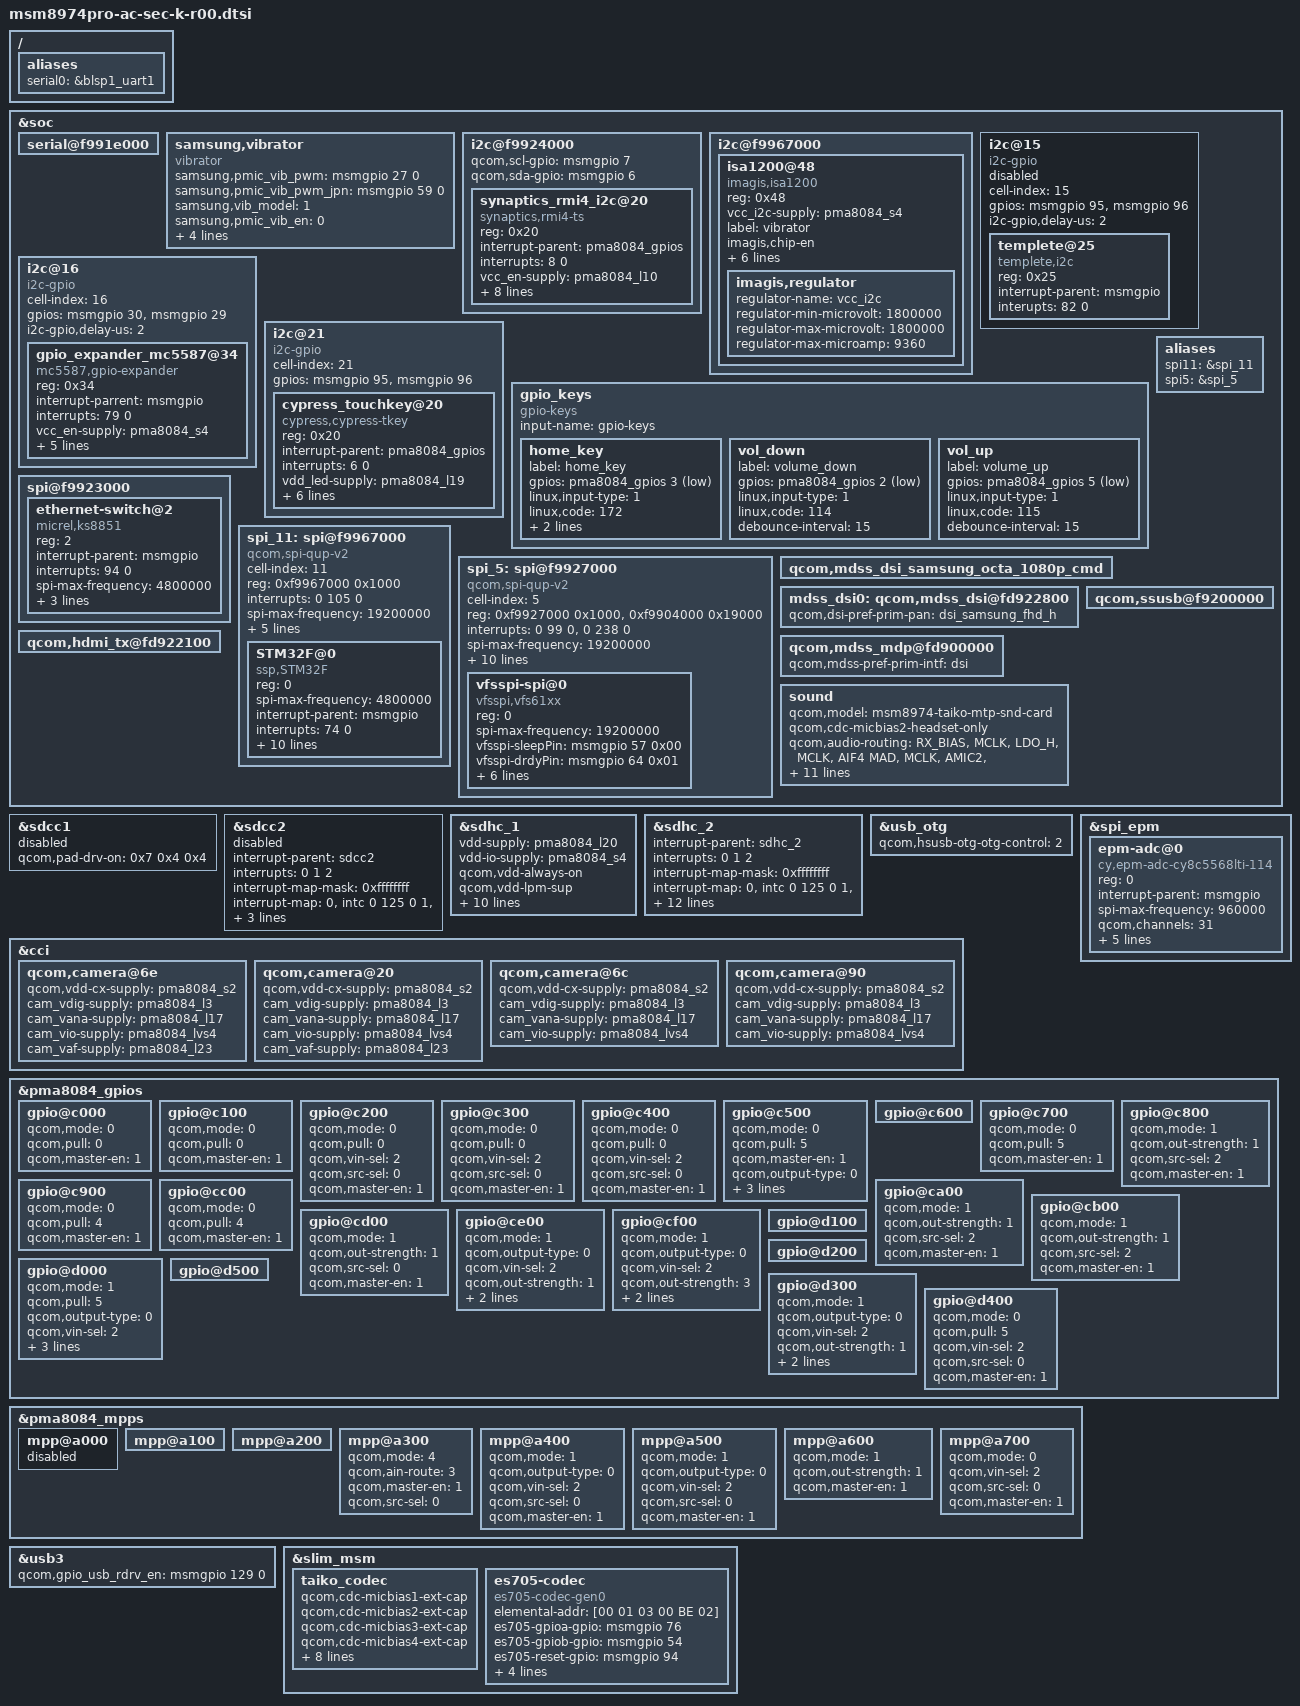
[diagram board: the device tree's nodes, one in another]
/* Copyright (c) 2013, The Linux Foundation. All rights reserved.
 *
 * This program is free software; you can redistribute it and/or modify
 * it under the terms of the GNU General Public License version 2 and
 * only version 2 as published by the Free Software Foundation.
 *
 * This program is distributed in the hope that it will be useful,
 * but WITHOUT ANY WARRANTY; without even the implied warranty of
 * MERCHANTABILITY or FITNESS FOR A PARTICULAR PURPOSE.  See the
 * GNU General Public License for more details.
 */

/*/include/ "msm8974-camera-sensor-mtp.dtsi"*/
/include/ "msm8974pro-sii8240_mhl-k-r00.dtsi"

/ {
	aliases {
		serial0 = &blsp1_uart1;
	};
};

&soc {
	serial@f991e000 {
		status = "ok";
	};
	
	samsung,vibrator {
		compatible = "vibrator";
		samsung,pmic_vib_pwm = <&msmgpio 27 0>;
		samsung,pmic_vib_pwm_jpn = <&msmgpio 59 0>;
		samsung,vib_model = <1>;
		samsung,pmic_vib_en = <0>;
		samsung,pmic_haptic_pwr_en = <0>;
		samsung,is_pmic_vib_pwm = <0>;
		samsung,pwm_period_us = <40>;
		samsung,duty_us = <36>;
		status = "ok";
	};

	i2c@f9924000 {
	qcom,scl-gpio = <&msmgpio 7 0>;
	qcom,sda-gpio = <&msmgpio 6 0>;

	synaptics_rmi4_i2c@20 {
			compatible = "synaptics,rmi4-ts";
			reg = <0x20>;
			interrupt-parent = <&pma8084_gpios>;
			interrupts = <8 0>;
			vcc_en-supply = <&pma8084_l10>;
			synaptics,supply-num = <1>;		/* the number of regulators */
			synaptics,supply-name = "8084_l10";	/* the name of regulators, in power-on order */
			synaptics,external_ldo = <&pma8084_gpios 9 0x1>;
			synaptics,irq-gpio = <&pma8084_gpios 8 0x1>;
			synaptics,tsp-coords = <1079 1919>;
			synaptics,i2c-pull-up = <1>;
			synaptics,tsp-project = "K";
			synaptics,tsp-extra_config = <1 0 0 0>;/* <"pwrctrl", "N", "N", "N"> */
		};
	};
	
	i2c@f9967000 {
	   isa1200@48 {
     status = "okay";
	   reg = <0x48>;
	   vcc_i2c-supply = <&pma8084_s4>;
	   compatible = "imagis,isa1200";
	   label = "vibrator";
	   imagis,chip-en;
	   imagis,need-pwm-clk;
	   imagis,ext-clk-en;
	   imagis,hap-en-gpio = <&msmgpio 86 0x00>;
	   imagis,max-timeout = <15000>;
	   imagis,pwm-div = <256>;
	   imagis,mode-ctrl = <2>;
	   imagis,regulator {
			  	regulator-name = "vcc_i2c";
				  regulator-min-microvolt = <1800000>;
				  regulator-max-microvolt = <1800000>;
				  regulator-max-microamp = <9360>;
			};
		};
	};
/*
	i2c@f9928000 {
	  	gpio_expander_mc5587@34 {
			compatible = "mc5587,gpio-expander";
			reg = <0x34>;
			vcc_en-supply = <&pma8084_s4>;
		};
	};
*/

	/* templete of i2c-gpio */
	  i2c@15{
	      cell-index = <15>;
	      compatible = "i2c-gpio";
	      gpios = <&msmgpio 95 0  /*SDA*/
        	      &msmgpio 96 0  /*SCL*/
	             >;
	      i2c-gpio,delay-us = <2>;
	      #address-cells = <1>;
	      #size-cells = <0>;
		status = "disabled"; /*just templete, and then disable it
			       don't care all property despite of duplication */
	      templete@25{
              compatible = "templete,i2c";
              reg = <0x25>;
              interrupt-parent = <&msmgpio>;
              interupts= <82 0>;
	    };
	};

	i2c@16 {
		cell-index = <16>;
		compatible = "i2c-gpio";
		gpios = <&msmgpio 30 0  /*SDA*/
			&msmgpio 29 0  /*SCL*/
			>;
		i2c-gpio,delay-us = <2>;
		#address-cells = <1>;
		#size-cells = <0>;

		gpio_expander_mc5587@34 {
			compatible = "mc5587,gpio-expander";
			reg = <0x34>;
			interrupt-parrent = <&msmgpio>;
			interrupts = <79 0>;
			vcc_en-supply = <&pma8084_s4>;
			mc5587,gpio_start = <300>;
			mc5587,ngpio = <18>;
			mc5587,irq-gpio = <&msmgpio 79 0>;
			mc5587,irq-base = <529>;
			mc5587,reset-gpio = <&msmgpio 145 0>;
		};
	};

	i2c@21 {
		cell-index = <21>;
		compatible = "i2c-gpio";
		gpios = <&msmgpio 95 0 /* sda */
			 &msmgpio 96 0 /* scl */
			>;
		#address-cells = <1>;
		#size-cells = <0>;

		cypress_touchkey@20 {
			compatible = "cypress,cypress-tkey";
			reg = <0x20>;
			interrupt-parent = <&pma8084_gpios>;
			interrupts = <6 0>;
			vdd_led-supply = <&pma8084_l19>;
			vcc_en-supply = <&pma8084_lvs3>;
			cypress,scl-gpio = <&msmgpio 96 0x00>;
			cypress,sda-gpio = <&msmgpio 95 0x00>;
			cypress,irq-gpio = <&pma8084_gpios 6 0x1>;
			cypress,tkey-keycodes = <254 158>;
			cypress,i2c-pull-up = <1>;
		};
	};

	gpio_keys {
		compatible = "gpio-keys";
		input-name = "gpio-keys";

		home_key {
			label = "home_key";
			gpios = <&pma8084_gpios 3 0x1>;
			linux,input-type = <1>;
			linux,code = <172>;
			gpio-key,wakeup;
			debounce-interval = <15>;
		};

		vol_down {
			label = "volume_down";
			gpios = <&pma8084_gpios 2 0x1>;
			linux,input-type = <1>;
			linux,code = <114>;
			debounce-interval = <15>;
		};

		vol_up {
			label = "volume_up";
			gpios = <&pma8084_gpios 5 0x1>;
			linux,input-type = <1>;
			linux,code = <115>;
			debounce-interval = <15>;
		};
	};

	spi@f9923000 {
		ethernet-switch@2 {
			compatible = "micrel,ks8851";
			reg = <2>;
			interrupt-parent = <&msmgpio>;
			interrupts = <94 0>;
			spi-max-frequency = <4800000>;
			rst-gpio = <&pma8084_mpps 6 0>;
			vdd-io-supply = <&spi_eth_vreg>;
			vdd-phy-supply = <&spi_eth_vreg>;
		};
	};

	aliases {
		spi11 = &spi_11;
	};
	spi_11: spi@f9967000 {
		compatible = "qcom,spi-qup-v2";
		cell-index = <11>;
		#address-cells = <1>;
		#size-cells = <0>;
		reg = <0xf9967000 0x1000>;
		interrupt-names = "spi_irq";
		interrupts = <0 105 0>;
		spi-max-frequency = <19200000>;

		qcom,gpio-mosi = <&msmgpio 81 0>;
		qcom,gpio-miso = <&msmgpio 82 0>;
		qcom,gpio-clk  = <&msmgpio 84 0>;
		qcom,gpio-cs0  = <&msmgpio 83 0>;

		qcom,master-id = <84>;

		STM32F@0 {
			compatible = "ssp,STM32F";
			reg = <0>;
			spi-max-frequency = <4800000>;
			interrupt-parent = <&msmgpio>;
			interrupts = <74 0>;
			hub_vreg-supply = <&pma8084_lvs1>;
			psns_vreg-supply = <&pma8084_l18>;
			ssp,mcu_int1-gpio = <&msmgpio 74 0x00>;
			ssp,mcu_int2-gpio = <&msmgpio 86 0x00>;
			ssp,ap_int-gpio = <&msmgpio 89 0x00>;
			ssp,rst-gpio = <&msmgpio 91 0x00>;
			ssp,acc-position = <6>;
			ssp,mag-position = <3>;
			ssp,sns-combination = <0>;
			ssp,ap-rev=<5>;
		};
	};

	aliases {
		spi5 = &spi_5;
	};
	spi_5: spi@f9927000 {
		compatible = "qcom,spi-qup-v2";
		cell-index = <5>;
		#address-cells = <1>;
		#size-cells = <0>;
		reg = <0xf9927000 0x1000>,
			<0xf9904000 0x19000>;
		reg-names = "spi_physical", "spi_bam_physical";
		interrupt-names = "spi_irq", "spi_bam_irq";
		interrupts = <0 99 0>, <0 238 0>;
		spi-max-frequency = <19200000>;

		qcom,gpio-mosi = <&msmgpio 23 0>;
		qcom,gpio-miso = <&msmgpio 24 0>;
		qcom,gpio-clk  = <&msmgpio 26 0>;
		qcom,gpio-cs0  = <&msmgpio 25 0>;

		qcom,infinite-mode = <0>;
		qcom,use-bam;
		qcom,ver-reg-exists;
		qcom,bam-consumer-pipe-index = <20>;
		qcom,bam-producer-pipe-index = <21>;
		qcom,master-id = <86>;

		vfsspi-spi@0 {
			compatible = "vfsspi,vfs61xx";
			reg = <0>;
			spi-max-frequency = <19200000>;
			vfsspi-sleepPin = <&msmgpio 57 0x00>;
			vfsspi-drdyPin = <&msmgpio 64 0x01>;
			vfsspi-ldoPin = <&msmgpio 130 0x00>;
			vfsspi-ldocontrol = <1>;
			vfsspi-mosipin = <23>;
			vfsspi-misopin = <24>;
			vfsspi-cspin = <25>;
			vfsspi-clkpin = <26>;
		};
	};

	qcom,mdss_dsi_samsung_octa_1080p_cmd {

		status = "ok";
		
	};
	
	mdss_dsi0: qcom,mdss_dsi@fd922800 {

		qcom,dsi-pref-prim-pan = <&dsi_samsung_fhd_h>;		
	};
	
	qcom,mdss_mdp@fd900000 {
		qcom,mdss-pref-prim-intf = "dsi";
	};
		

	qcom,ssusb@f9200000 {
		/*vbus_dwc3-supply = <&pm8941_mvs1>;*/
	};

	qcom,hdmi_tx@fd922100 {
		status = "ok";
	};

	sound {
		qcom,model = "msm8974-taiko-mtp-snd-card";
		qcom,cdc-micbias2-headset-only;

		qcom,audio-routing =
			"RX_BIAS", "MCLK",
			"LDO_H", "MCLK",
			"AIF4 MAD", "MCLK",
			"AMIC2", "MIC BIAS3 External",
			"MIC BIAS3 External", "Headset Mic",
			"DMIC1", "MIC BIAS1 External",
			"MIC BIAS1 External", "Digital Mic1",
			"DMIC2", "Main Mic Bias",
			"Main Mic Bias", "Main Mic",
			"DMIC3", "MIC BIAS3 External",
			"MIC BIAS3 External", "Digital Mic3",
			"DMIC4", "MIC BIAS1 External",
			"MIC BIAS1 External", "Sub Mic",
			"DMIC5", "MIC BIAS4 External",
			"MIC BIAS4 External", "Digital Mic5",
			"DMIC6", "MIC BIAS2 External",
			"MIC BIAS2 External", "Third Mic";
	};
};


&sdcc1 {
       status = "disabled";
};

&sdcc2 {
	#address-cells = <0>;
	interrupt-parent = <&sdcc2>;
	interrupts = <0 1 2>;
	#interrupt-cells = <1>;
	interrupt-map-mask = <0xffffffff>;
	interrupt-map = <0 &intc 0 125 0
			1 &intc 0 220 0
			2 &msmgpio 62 0x3>;
	interrupt-names = "core_irq", "bam_irq", "status_irq";
	cd-gpios = <&msmgpio 62 0x1>;
	status = "disabled";
};

&sdhc_1 {
	vdd-supply = <&pma8084_l20>;
	vdd-io-supply = <&pma8084_s4>;

	qcom,vdd-always-on;
	qcom,vdd-lpm-sup;
	qcom,vdd-voltage-level = <2950000 2950000>;
	qcom,vdd-current-level = <800 500000>;

	qcom,vdd-io-always-on;
	qcom,vdd-io-voltage-level = <1800000 1800000>;
	qcom,vdd-io-current-level = <250 154000>;

	qcom,pad-pull-on = <0x0 0x3 0x3>; /* no-pull, pull-up, pull-up */
	qcom,pad-pull-off = <0x0 0x3 0x3>; /* no-pull, pull-up, pull-up */
	qcom,pad-drv-on = <0x7 0x4 0x4>; /* 16mA, 10mA, 10mA */
	qcom,pad-drv-off = <0x0 0x0 0x0>; /* 2mA, 2mA, 2mA */

	qcom,nonremovable;
	status = "ok";
};

&sdhc_2 {
	#address-cells = <0>;
	interrupt-parent = <&sdhc_2>;
	interrupts = <0 1 2>;
	#interrupt-cells = <1>;
	interrupt-map-mask = <0xffffffff>;
	interrupt-map = <0 &intc 0 125 0
			1 &intc 0 221 0
			2 &msmgpio 62 0x3>;
	interrupt-names = "hc_irq", "pwr_irq", "status_irq";
	cd-gpios = <&msmgpio 62 0x1>;

	vdd-supply = <&pma8084_l21>;
	vdd-io-supply = <&pma8084_l13>;

	qcom,vdd-voltage-level = <2950000 2950000>;
	qcom,vdd-current-level = <9000 800000>;

	qcom,vdd-io-voltage-level = <1800000 2950000>;
	qcom,vdd-io-current-level = <6 22000>;

	qcom,pad-pull-on = <0x0 0x3 0x3>; /* no-pull, pull-up, pull-up */
	qcom,pad-pull-off = <0x0 0x3 0x3>; /* no-pull, pull-up, pull-up */
	qcom,pad-drv-on = <0x7 0x4 0x4>; /* 16mA, 10mA, 10mA */
	qcom,pad-drv-off = <0x0 0x0 0x0>; /* 2mA, 2mA, 2mA */
	status = "ok";
};

/* Drive strength recommendations for clock line from hardware team is 10 mA.
 * But since the driver has been been using the below values from the start
 * without any problems, continue to use those.
 */
&sdcc1 {
	qcom,pad-drv-on = <0x7 0x4 0x4>; /* 16mA, 10mA, 10mA */
};

&sdcc2 {
	qcom,pad-drv-on = <0x7 0x4 0x4>; /* 16mA, 10mA, 10mA */
};

&usb_otg {
	qcom,hsusb-otg-otg-control = <2>;
};

&spi_epm {
	epm-adc@0 {
		compatible = "cy,epm-adc-cy8c5568lti-114";
		reg = <0>;
		interrupt-parent = <&msmgpio>;
		spi-max-frequency = <960000>;
		qcom,channels = <31>;
		qcom,gain = <100 100 100 50 100 100 1 100 1 50
				1 100 1 100 50 50 50 50 50 50
				100 50 100 50 50 50 50 50 50 50
				50>;
		qcom,rsense = <2 2 2 200 20 2 1 2 1 30
				1 10 1 30 50 30 500 30 100 30
				100 500 20 200 1000 20 1000 1000 70 200
				50>;
		qcom,channel-type = <0x1540>;
	};
};

&cci {
	qcom,camera@6e {
		qcom,vdd-cx-supply = <&pma8084_s2>;
		cam_vdig-supply = <&pma8084_l3>;
		cam_vana-supply = <&pma8084_l17>;
		cam_vio-supply = <&pma8084_lvs4>;
		cam_vaf-supply = <&pma8084_l23>;
	};

	qcom,camera@20 {
		qcom,vdd-cx-supply = <&pma8084_s2>;
		cam_vdig-supply = <&pma8084_l3>;
		cam_vana-supply = <&pma8084_l17>;
		cam_vio-supply = <&pma8084_lvs4>;
		cam_vaf-supply = <&pma8084_l23>;
	};

	qcom,camera@6c {
		qcom,vdd-cx-supply = <&pma8084_s2>;
		cam_vdig-supply = <&pma8084_l3>;
		cam_vana-supply = <&pma8084_l17>;
		cam_vio-supply = <&pma8084_lvs4>;
	};

	qcom,camera@90 {
		qcom,vdd-cx-supply = <&pma8084_s2>;
		cam_vdig-supply = <&pma8084_l3>;
		cam_vana-supply = <&pma8084_l17>;
		cam_vio-supply = <&pma8084_lvs4>;
	};
};

&pma8084_gpios {
	gpio@c000 { /* GPIO 1 */
		/* Unused */
		qcom,mode = <0>;		/* Digital input */
		qcom,pull = <0>;		/* Pull up 30 uA */
		qcom,master-en = <1>;
	};

	gpio@c100 { /* GPIO 2 */
		/* Unused */
		qcom,mode = <0>;		/* Digital input */
		qcom,pull = <0>;		/* Pull up 30 uA */
		qcom,master-en = <1>;
	};

	gpio@c200 { /* GPIO 3 */
		/* Snapshot button */
		qcom,mode = <0>;		/* Digital input */
		qcom,pull = <0>;		/* Pull up 30 uA */
		qcom,vin-sel = <2>;		/* PMA8084 S4 = 1.8 V */
		qcom,src-sel = <0>;		/* Constant */
		qcom,master-en = <1>;
	};

	gpio@c300 { /* GPIO 4 */
		/* Focus button */
		qcom,mode = <0>;		/* Digital input */
		qcom,pull = <0>;		/* Pull up 30 uA */
		qcom,vin-sel = <2>;		/* PMA8084 S4 = 1.8 V */
		qcom,src-sel = <0>;		/* Constant */
		qcom,master-en = <1>;
	};

	gpio@c400 { /* GPIO 5 */
		/* Volume up button */
		qcom,mode = <0>;		/* Digital input */
		qcom,pull = <0>;		/* Pull up 30 uA */
		qcom,vin-sel = <2>;		/* PMA8084 S4 = 1.8 V */
		qcom,src-sel = <0>;		/* Constant */
		qcom,master-en = <1>;
	};

	gpio@c500 { /* GPIO 6 */
		/* Touchkey IRQ */
		qcom,mode = <0>;		/* Digital input */
		qcom,pull = <5>;		/* Pull none */
		qcom,master-en = <1>;
		qcom,output-type = <0>;
		qcom,vin-sel = <2>;
		qcom,out-strength = <2>;
		qcom.src-sel = <3>;
	};

	gpio@c600 { /* GPIO 7 */
		/* GRFC_12 */
	};

	gpio@c700 { /* GPIO 8 */
		/* Touchscreen IRQ */
		qcom,mode = <0>;		/* Digital input */
		qcom,pull = <5>;		/* Pull none */
		qcom,master-en = <1>;
	};

	gpio@c800 { /* GPIO 9 */
		/* Touchscreen external LDO enable */
		qcom,mode = <1>;		/* Digital output */
		qcom,out-strength = <1>;	/* Low */
		qcom,src-sel = <2>;		/* Function 1  */
		qcom,master-en = <1>;
	};

	gpio@c900 { /* GPIO 10 */
		/* NFC clock request */
		qcom,mode = <0>;		/* Digital input */
		qcom,pull = <4>;		/* Pull down */
		qcom,master-en = <1>;
	};

	gpio@ca00 { /* GPIO 11 */
		/* Unused */
		qcom,mode = <1>;		/* Digital output */
		qcom,out-strength = <1>;	/* Low */
		qcom,src-sel = <2>;		/* Function 1  */
		qcom,master-en = <1>;
	};

	gpio@cb00 { /* GPIO 12 */
		/* Unused */
		qcom,mode = <1>;		/* Digital output */
		qcom,out-strength = <1>;	/* Low */
		qcom,src-sel = <2>;		/* Function 1  */
		qcom,master-en = <1>;
	};

	gpio@cc00 { /* GPIO 13 */
		/* TS_CHGR_IN */
		qcom,mode = <0>;		/* Digital input */
		qcom,pull = <4>;		/* Pull down */
		qcom,master-en = <1>;
	};

	gpio@cd00 { /* GPIO 14 */
		/* Unused */
		/* LCD_EN */
		qcom,mode = <1>;		/* Digital output */
		qcom,out-strength = <1>;	/* Low */
		qcom,src-sel = <0>;		/* Function 1  */
		qcom,master-en = <1>;
	};

	gpio@ce00 { /* GPIO 15 */
		/* Codec clock */
		qcom,mode = <1>;		/* Digital output */
		qcom,output-type = <0>;		/* CMOS */
		qcom,vin-sel = <2>;		/* PMA8084 S4 = 1.8 V */
		qcom,out-strength = <1>;	/* Low */
		qcom,src-sel = <2>;		/* Function 1 - DIVCLK1 */
		qcom,master-en = <1>;
	};

	gpio@cf00 { /* GPIO 16 */
		/* Haptics clock */
		qcom,mode = <1>;		/* Digital output */
		qcom,output-type = <0>;		/* CMOS */
		qcom,vin-sel = <2>;		/* PMA8084 S4 = 1.8 V */
		qcom,out-strength = <3>;	/* High */
		qcom,src-sel = <3>;       	/* Function 2 - SLEEPCLK3  */
		qcom,master-en = <1>;
	};

	gpio@d000 { /* GPIO 17 */
		/* QPA clock */
		/* LCD_RESET */
		qcom,mode = <1>;		/* Digital output */
		qcom,pull = <5>;		/* Pull down */
		qcom,output-type = <0>;		/* CMOS */		
		qcom,vin-sel = <2>;		/* PMA8084 S4 = 1.8 V */
		qcom,out-strength = <1>;	/* Low */
		qcom,src-sel = <0>;		/* constant */
		qcom,master-en = <1>;	
	};

	gpio@d100 { /* GPIO 18 */
		/* Unused */
	};

	gpio@d200 { /* GPIO 19 */
		/* BOOST_BYP */
	};

	gpio@d300 { /* GPIO 20 */
		/* Display enable */
		qcom,mode = <1>;		/* Digital output */
		qcom,output-type = <0>;		/* CMOS */
		qcom,vin-sel = <2>;		/* PMA8084 S4 = 1.8 V */
		qcom,out-strength = <1>;	/* Low */
		qcom,src-sel = <0>;		/* Constant */
		qcom,master-en = <1>;
	};

	gpio@d400 { /* GPIO 21 */
		/* Fuel Alert */
		qcom,mode = <0>;		/* Digital input */
		qcom,pull = <5>;		/* QPNP_PIN_PULL_NO */
		qcom,vin-sel = <2>;		/* PMA8084 S4 = 1.8 V */
		qcom,src-sel = <0>;		/* Constant */
		qcom,master-en = <1>;
	};

	gpio@d500 { /* GPIO 22 */
		/* BATT_REM_ALARM */
	};
};

&pma8084_mpps {
	mpp@a000 { /* MPP 1 */
		/* SDC_UIM_VBIAS */
		status = "disabled";
	};

	mpp@a100 { /* MPP 2 */
		/* PM8941_PON_1 */
	};

	mpp@a200 { /* MPP 3 */
		/* VREF_DAC */
	};

	mpp@a300 { /* MPP 4 */
		qcom,mode = <4>; /* AIN input */
		qcom,ain-route = <3>; /* AMUX 8 */
		qcom,master-en = <1>;/* Enable MPP4 */
		qcom,src-sel = <0>; /* Function constant */
	};

	mpp@a400 { /* MPP 5 */
		qcom,mode = <1>; /* DIG_OUT */
		qcom,output-type = <0>; /* CMOS */
		qcom,vin-sel = <2>; /* PM8941_S3 1.8V > 1.6V */
		qcom,src-sel = <0>; /* CONSTANT */
		qcom,master-en = <1>; /* ENABLE MPP */
	};

	mpp@a500 { /* MPP 6 */
		/* SPI ethernet enable */
		qcom,mode = <1>;		/* Digital output */
		qcom,output-type = <0>;		/* CMOS */
		qcom,vin-sel = <2>;		/* PMA8084 S4 = 1.8V > 1.6V */
		qcom,src-sel = <0>;		/* Constant */
	/*	qcom,out-strength = <1>;*/	/* Low */
		qcom,master-en = <1>;
	};

	mpp@a600 { /* MPP 7 */
		/* NFC disable */
		qcom,mode = <1>;		/* Digital output */
		qcom,out-strength = <1>;	/* Low */
		qcom,master-en = <1>;
	};

	mpp@a700 { /* MPP 8 */
		qcom,mode = <0>; /* DIG_IN */
		qcom,vin-sel = <2>;		/* PMA8084 S4 = 1.8V > 1.6V */
		qcom,src-sel = <0>;		/* Constant */
		qcom,master-en = <1>;
	};
};

&usb3 {
	qcom,gpio_usb_rdrv_en = <&msmgpio 129 0>;
};

&slim_msm {
	taiko_codec {
		qcom,cdc-micbias1-ext-cap;
		qcom,cdc-micbias2-ext-cap;
		qcom,cdc-micbias3-ext-cap;
		qcom,cdc-micbias4-ext-cap;

		qcom,cdc-micbias1-cfilt-sel = <0x0>;
		qcom,cdc-micbias2-cfilt-sel = <0x0>;
		qcom,cdc-micbias3-cfilt-sel = <0x0>;
		qcom,cdc-micbias4-cfilt-sel = <0x0>;

		/*
		 * Liquid has external spkrdrv supply. Give a dummy supply to
		 * make codec driver's happy.
		 */
		cdc-vdd-spkdrv-supply = <&vph_pwr_vreg>;
		qcom,cdc-vdd-spkdrv-voltage = <0 0>;
		qcom,cdc-vdd-spkdrv-current = <0>;

		qcom,cdc-on-demand-supplies = "cdc-vdd-spkdrv";
	};
	es705-codec {
		compatible = "es705-codec-gen0";
		elemental-addr = [00 01 03 00 BE 02];

		es705-gpioa-gpio = <&msmgpio 76 0>;
		es705-gpiob-gpio = <&msmgpio 54 0>;
		es705-reset-gpio = <&msmgpio 94 0>;			
		es705-wakeup-gpio = <&msmgpio 85 0>;

		es705-slim-ifd = "es705-ifd";
		es705-slim-ifd-elemental-addr = [00 00 03 00 BE 02];
	};	
};
